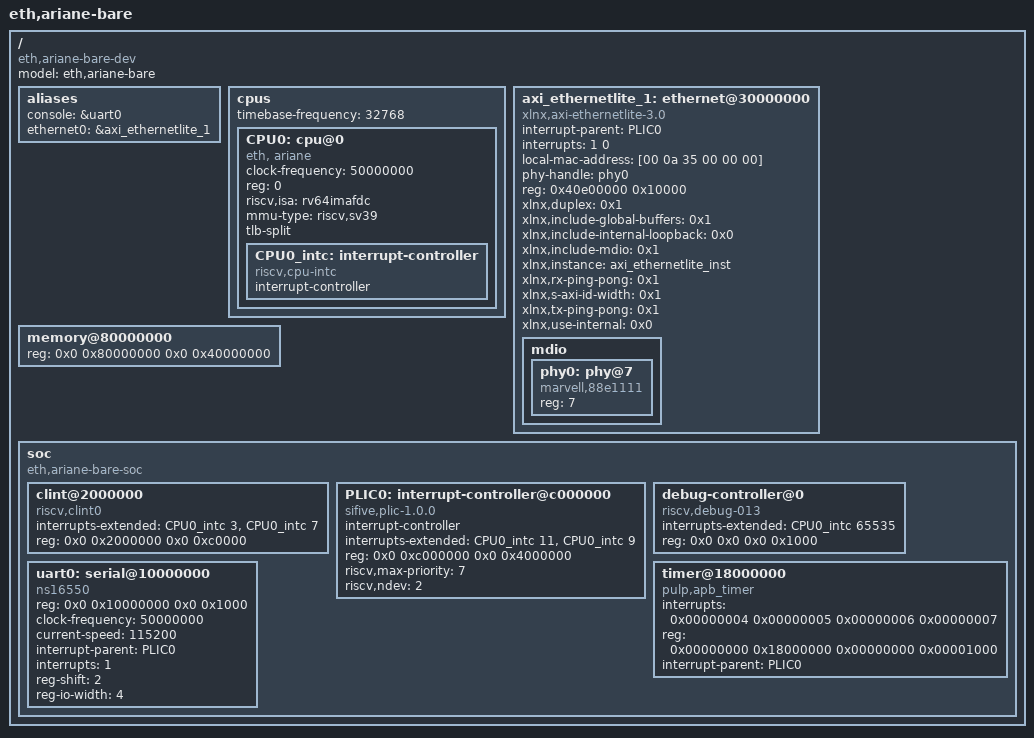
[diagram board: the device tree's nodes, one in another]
/dts-v1/;

/ {
  #address-cells = <2>;
  #size-cells = <2>;
  compatible = "eth,ariane-bare-dev";
  model = "eth,ariane-bare";

  aliases {
      console = &uart0;
      ethernet0 = &axi_ethernetlite_1;
  };
  cpus {
    #address-cells = <1>;
    #size-cells = <0>;
    timebase-frequency = <32768>; // 32.768 kHz
    CPU0: cpu@0 {
      clock-frequency = <50000000>; // 50 MHz
      device_type = "cpu";
      reg = <0>;
      status = "okay";
      compatible = "eth, ariane", "riscv";
      riscv,isa = "rv64imafdc";
      mmu-type = "riscv,sv39";
      tlb-split;
      // HLIC - hart local interrupt controller
      CPU0_intc: interrupt-controller {
        #interrupt-cells = <1>;
        interrupt-controller;
        compatible = "riscv,cpu-intc";
      };
    };
  };

  //chosen {
   //   stdout-path = "uart:115200n8";
  //};

//https://xilinx-wiki.atlassian.net/wiki/spaces/A/pages/18841972/Linux+Emaclite+Driver
axi_ethernetlite_1: ethernet@30000000 {
                       compatible = "xlnx,axi-ethernetlite-3.0", "xlnx,xps-ethernetlite-1.00.a";
                       device_type = "network";
                       //interrupt-parent = <&axi_intc_1>;
                       interrupt-parent = <&PLIC0>;
                       interrupts = <1 0>;
                       local-mac-address = [00 0a 35 00 00 00];
                       phy-handle = <&phy0>;
                       reg = <0x40e00000 0x10000>;
                       xlnx,duplex = <0x1>;
                       xlnx,include-global-buffers = <0x1>;
                       xlnx,include-internal-loopback = <0x0>;
                       xlnx,include-mdio = <0x1>;
                       xlnx,instance = "axi_ethernetlite_inst";
                       xlnx,rx-ping-pong = <0x1>;
                       xlnx,s-axi-id-width = <0x1>;
                       xlnx,tx-ping-pong = <0x1>;
                       xlnx,use-internal = <0x0>;
                       mdio {
                               #address-cells = <1>;
                               #size-cells = <0>;
                               phy0: phy@7 {
                                       compatible = "marvell,88e1111";
                                       device_type = "ethernet-phy";
                                       reg = <7>;
                               } ;
                       } ;
               } ;

//https://www.kernel.org/doc/Documentation/devicetree/bindings/net/xilinx_axienet.txt
//https://xilinx-wiki.atlassian.net/wiki/spaces/A/pages/18842485/Linux+AXI+Ethernet+driver#LinuxAXIEthernetdriver-Device-tree
//axi_ethernet_eth: ethernet@30000000 {
//		compatible = "xlnx,axi-ethernet-1.00.a";
//        //axistream-connected = <&axi_dma_1>;
//        //axistream-control-connected = <&axi_dma_1>;
//		device_type = "network";
//        interrupt-parent = <&PLIC0>;
//		interrupts = <2 0 1>;
//		//clocks = <&axi_clk>;
//		phy-mode = "rmii";
//        reg = <0x0 0x30000000 0x0 0x10000>;
 //       xlnx,phy-type = <0x4>;
//        xlnx,phyaddr = <0x1>;
//		xlnx,rxcsum = <0x2>;
//		xlnx,rxmem = <0x800>;
//		xlnx,txcsum = <0x2>;
//		phy-handle = <&phy0>;
//		axi_ethernetlite_0_mdio: mdio {
//			#address-cells = <1>;
//			#size-cells = <0>;
//			phy0: phy@0 {
//				device_type = "ethernet-phy";
//				reg = <1>;
//			};
//		};
//	};
    //compatible = "xlnx,axi-ethernet-1.00.a";
    //reg = <0x0 0x30000000 0x0 0x10000>;
    //status = "disabled";
    //interrupts = <0 22 4>;
    //clocks = <&clkc 30>, <&clkc 30>, <&clkc 13>;
    //clock-names = "pclk", "hclk", "tx_clk";
    //#address-cells = <1>;
    //#size-cells = <0>;

  memory@80000000 {
    device_type = "memory";
    //reg = <0x0 0x80000000 0x0 0x10000000>;
    reg = <0x0 0x80000000 0x0 0x40000000>;  //1 Gbyte
  };
  soc {
    #address-cells = <2>;
    #size-cells = <2>;
    compatible = "eth,ariane-bare-soc", "simple-bus";
    ranges;
    clint@2000000 {
      compatible = "riscv,clint0";
      interrupts-extended = <&CPU0_intc 3 &CPU0_intc 7>;
      reg = <0x0 0x2000000 0x0 0xc0000>;
      reg-names = "control";
    };
    // PLIC needs to be disabeld for tandem verification
    PLIC0: interrupt-controller@c000000 {
      #address-cells = <0>;
      #interrupt-cells = <1>;
      compatible = "sifive,plic-1.0.0", "riscv,plic0";
      interrupt-controller;
      interrupts-extended = <&CPU0_intc 11 &CPU0_intc 9>;
      reg = <0x0 0xc000000 0x0 0x4000000>;
      riscv,max-priority = <7>;
      riscv,ndev = <2>;
    };
    debug-controller@0 {
      compatible = "riscv,debug-013";
      interrupts-extended = <&CPU0_intc 65535>;
      reg = <0x0 0x0 0x0 0x1000>;
      reg-names = "control";
    };
    uart0: serial@10000000 {
      compatible = "ns16550";
      reg = <0x0 0x10000000 0x0 0x1000>;
      clock-frequency = <50000000>;
      current-speed = <115200>;
      interrupt-parent = <&PLIC0>;
      interrupts = <1>;
      reg-shift = <2>; // regs are ospaced on 32 bit boundary
      reg-io-width = <4>; // only 32-bit access are supported
    };
    timer@18000000 {
      compatible = "pulp,apb_timer";
      interrupts = <0x00000004 0x00000005 0x00000006 0x00000007>;
      reg = <0x00000000 0x18000000 0x00000000 0x00001000>;
      interrupt-parent = <&PLIC0>;
      reg-names = "control";
    };
    }; //SOC
}; //main

//&gem0 {
//    status = "okay";
//    phy-mode = "rgmii-id";
//    phy-handle = <&ethernet_phy>;
//    //pinctrl-names = "default";
//    //pinctrl-0 = <&pinctrl_gem0_default>;
//    //phy-reset-gpio = <&gpio0 11 0>;
//    //phy-reset-active-low;
//
//    ethernet_phy: ethernet-phy@0 {
//        reg = <0>;
//        device_type = "ethernet-phy";
//    };
//}; //gem




